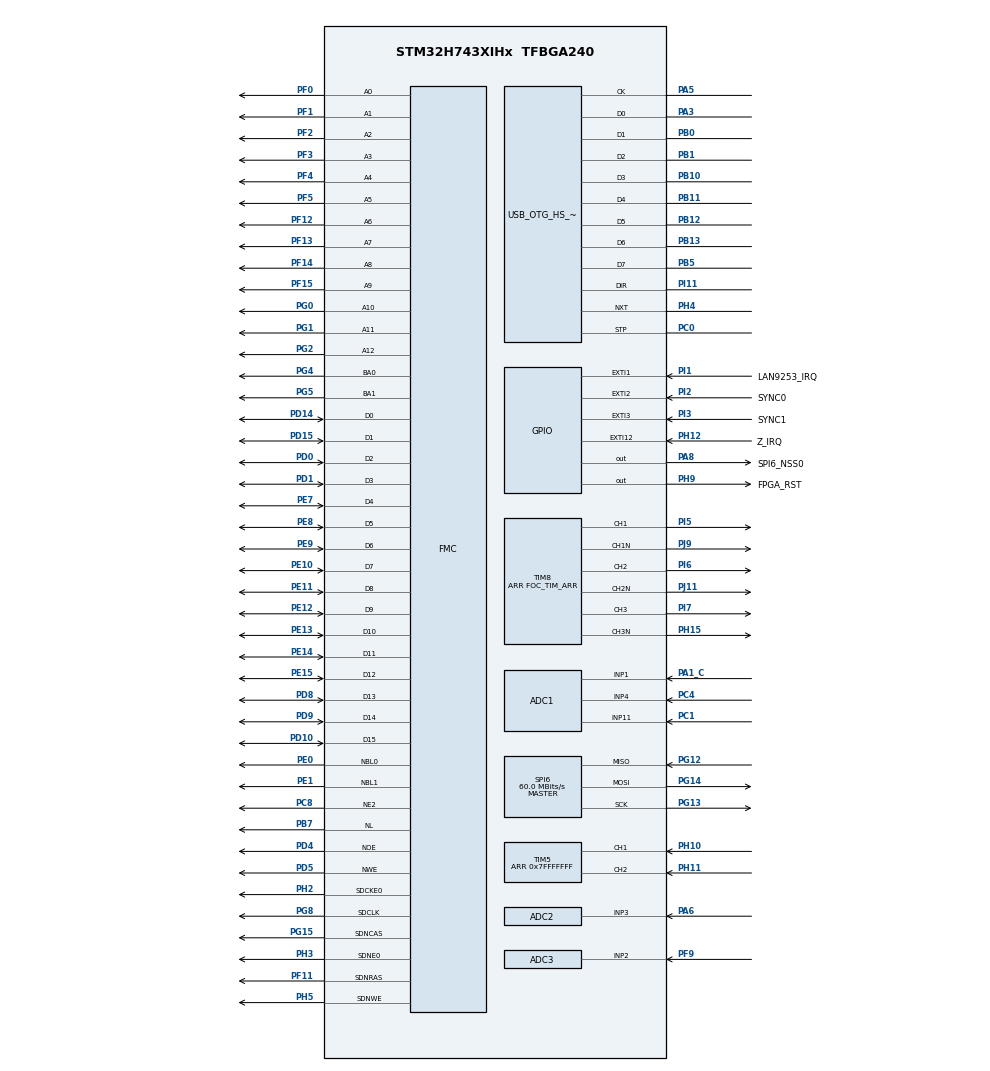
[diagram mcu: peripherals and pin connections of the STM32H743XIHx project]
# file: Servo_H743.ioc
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ADC1.Channel-12\#ChannelRegularConversion=ADC_CHANNEL_4
ADC1.Channel-13\#ChannelRegularConversion=ADC_CHANNEL_11
ADC1.ContinuousConvMode=ENABLE
ADC1.ConversionDataManagement=ADC_CONVERSIONDATA_DMA_CIRCULAR
ADC1.EnableInjectedConversion=ENABLE
ADC1.EnableInjectedOversampling=ENABLE
ADC1.EnableRegularConversion=ENABLE
ADC1.ExternalTrigConv=ADC_EXTERNALTRIG_T8_TRGO
ADC1.InjNumberOfConversion=1
ADC1.InjOversamplingRatio=4
ADC1.InjOversamplingRightShift=ADC_RIGHTBITSHIFT_2
ADC1.InjectedChannel-9\#ChannelInjectedConversion=ADC_CHANNEL_1
ADC1.InjectedOffsetNumber-9\#ChannelInjectedConversion=ADC_OFFSET_NONE
ADC1.InjectedOffsetSaturation-9\#ChannelInjectedConversion=DISABLE
ADC1.InjectedOffsetSignedSaturation-9\#ChannelInjectedConversion=DISABLE
ADC1.InjectedRank-9\#ChannelInjectedConversion=1
ADC1.InjectedSamplingTime-9\#ChannelInjectedConversion=ADC_SAMPLETIME_1CYCLE_5
ADC1.NbrOfConversion=2
ADC1.NbrOfConversionFlag=1
ADC1.OffsetNumber-12\#ChannelRegularConversion=ADC_OFFSET_NONE
ADC1.OffsetNumber-13\#ChannelRegularConversion=ADC_OFFSET_NONE
ADC1.OffsetSignedSaturation-12\#ChannelRegularConversion=DISABLE
ADC1.OffsetSignedSaturation-13\#ChannelRegularConversion=DISABLE
ADC1.Overrun=ADC_OVR_DATA_OVERWRITTEN
ADC1.OversamplingMode=ENABLE
ADC1.Rank-12\#ChannelRegularConversion=1
ADC1.Rank-13\#ChannelRegularConversion=2
ADC1.Ratio=4
ADC1.RightBitShift=ADC_RIGHTBITSHIFT_2
ADC1.SamplingTime-12\#ChannelRegularConversion=ADC_SAMPLETIME_8CYCLES_5
ADC1.SamplingTime-13\#ChannelRegularConversion=ADC_SAMPLETIME_8CYCLES_5
ADC1.master=1
ADC2.ClockPrescaler=ADC_CLOCK_ASYNC_DIV1
ADC2.EnableInjectedConversion=ENABLE
ADC2.EnableInjectedOversampling=ENABLE
ADC2.EnableRegularConversion=DISABLE
ADC2.ExternalTrigInjecConv=ADC_INJECTED_SOFTWARE_START
ADC2.InjNumberOfConversion=1
ADC2.InjOversamplingRatio=4
ADC2.InjOversamplingRightShift=ADC_RIGHTBITSHIFT_2
ADC2.InjectedChannel-1\#ChannelInjectedConversion=ADC_CHANNEL_3
ADC2.InjectedOffsetNumber-1\#ChannelInjectedConversion=ADC_OFFSET_NONE
ADC2.InjectedOffsetSaturation-1\#ChannelInjectedConversion=DISABLE
ADC2.InjectedOffsetSignedSaturation-1\#ChannelInjectedConversion=DISABLE
ADC2.InjectedRank-1\#ChannelInjectedConversion=1
ADC2.InjectedSamplingTime-1\#ChannelInjectedConversion=ADC_SAMPLETIME_1CYCLE_5
ADC3.EnableInjectedConversion=ENABLE
ADC3.EnableInjectedOversampling=ENABLE
ADC3.EnableRegularConversion=DISABLE
ADC3.InjNumberOfConversion=1
ADC3.InjOversamplingRatio=4
ADC3.InjOversamplingRightShift=ADC_RIGHTBITSHIFT_2
ADC3.InjectedChannel-3\#ChannelInjectedConversion=ADC_CHANNEL_2
ADC3.InjectedOffsetNumber-3\#ChannelInjectedConversion=ADC_OFFSET_NONE
ADC3.InjectedOffsetSaturation-3\#ChannelInjectedConversion=DISABLE
ADC3.InjectedOffsetSignedSaturation-3\#ChannelInjectedConversion=DISABLE
ADC3.InjectedRank-3\#ChannelInjectedConversion=1
ADC3.InjectedSamplingTime-3\#ChannelInjectedConversion=ADC_SAMPLETIME_1CYCLE_5
CORTEX_M7.AccessPermission_S-Cortex_Memory_Protection_Unit_Region1_Settings_S=MPU_REGION_PRIV_RW
CORTEX_M7.AccessPermission_S-Cortex_Memory_Protection_Unit_Region2_Settings_S=MPU_REGION_PRIV_RO
CORTEX_M7.BaseAddress_S-Cortex_Memory_Protection_Unit_Region1_Settings_S=0xC0000000
CORTEX_M7.BaseAddress_S-Cortex_Memory_Protection_Unit_Region2_Settings_S=0x64000000
CORTEX_M7.CPU_DCache=Enabled
CORTEX_M7.CPU_ICache=Enabled
CORTEX_M7.Enable_S-Cortex_Memory_Protection_Unit_Region1_Settings_S=MPU_REGION_ENABLE
CORTEX_M7.Enable_S-Cortex_Memory_Protection_Unit_Region2_Settings_S=MPU_REGION_ENABLE
CORTEX_M7.Enable_S-Cortex_Memory_Protection_Unit_Region3_Settings_S=__NULL
CORTEX_M7.IsBufferable_S-Cortex_Memory_Protection_Unit_Region1_Settings_S=MPU_ACCESS_BUFFERABLE
CORTEX_M7.IsBufferable_S-Cortex_Memory_Protection_Unit_Region2_Settings_S=MPU_ACCESS_NOT_BUFFERABLE
CORTEX_M7.IsBufferable_Spec=MPU_ACCESS_NOT_BUFFERABLE
CORTEX_M7.IsCacheable_S-Cortex_Memory_Protection_Unit_Region2_Settings_S=MPU_ACCESS_NOT_CACHEABLE
CORTEX_M7.IsCacheable_Spec=MPU_ACCESS_NOT_CACHEABLE
CORTEX_M7.Size_S-Cortex_Memory_Protection_Unit_Region1_Settings_S=MPU_REGION_SIZE_32MB
CORTEX_M7.Size_S-Cortex_Memory_Protection_Unit_Region2_Settings_S=MPU_REGION_SIZE_128KB
CORTEX_M7.default_mode_Activation=1
Dma.ADC1.0.Direction=DMA_PERIPH_TO_MEMORY
Dma.ADC1.0.EventEnable=DISABLE
Dma.ADC1.0.FIFOMode=DMA_FIFOMODE_ENABLE
Dma.ADC1.0.FIFOThreshold=DMA_FIFO_THRESHOLD_HALFFULL
Dma.ADC1.0.Instance=DMA1_Stream0
Dma.ADC1.0.MemBurst=DMA_MBURST_SINGLE
Dma.ADC1.0.MemDataAlignment=DMA_MDATAALIGN_WORD
Dma.ADC1.0.MemInc=DMA_MINC_ENABLE
Dma.ADC1.0.Mode=DMA_CIRCULAR
Dma.ADC1.0.PeriphBurst=DMA_PBURST_SINGLE
Dma.ADC1.0.PeriphDataAlignment=DMA_PDATAALIGN_WORD
Dma.ADC1.0.PeriphInc=DMA_PINC_DISABLE
Dma.ADC1.0.Polarity=HAL_DMAMUX_REQ_GEN_RISING
Dma.ADC1.0.Priority=DMA_PRIORITY_LOW
Dma.ADC1.0.RequestNumber=1
Dma.ADC1.0.SignalID=NONE
Dma.ADC1.0.SyncEnable=DISABLE
Dma.ADC1.0.SyncPolarity=HAL_DMAMUX_SYNC_NO_EVENT
Dma.ADC1.0.SyncRequestNumber=1
Dma.ADC1.0.SyncSignalID=NONE
Dma.Request0=ADC1
FMC.AddressHoldTime1=1
FMC.AddressSetupTime1=1
FMC.BusTurnAroundDuration1=0
FMC.CASLatency1=FMC_SDRAM_CAS_LATENCY_3
FMC.ColumnBitsNumber1=FMC_SDRAM_COLUMN_BITS_NUM_9
FMC.DataSetupTime1=8
FMC.ExitSelfRefreshDelay1=11
FMC.LoadToActiveDelay1=2
FMC.RCDDelay1=3
FMC.RPDelay1=3
FMC.ReadBurst1=FMC_SDRAM_RBURST_ENABLE
FMC.ReadPipeDelay1=FMC_SDRAM_RPIPE_DELAY_0
FMC.RowCycleDelay1=9
FMC.SDClockPeriod1=FMC_SDRAM_CLOCK_PERIOD_2
FMC.SelfRefreshTime1=7
FMC.WriteOperation1=FMC_WRITE_OPERATION_DISABLE
FMC.WriteRecoveryTime1=4
Mcu.Family=STM32H7
Mcu.Name=STM32H743XIHx
Mcu.Package=TFBGA240
Mcu.UserConstants=FOC_TIM_ARR,6000;FOC_DT,47;FOC_CTRL_FREQ,20000
NVIC.DMA1_Stream0_IRQn=true\:0\:0\:true\:false\:true\:false\:true\:true
NVIC.EXTI15_10_IRQn=true\:1\:0\:true\:false\:true\:true\:true\:true
NVIC.EXTI1_IRQn=true\:0\:0\:false\:false\:true\:true\:true\:true
NVIC.EXTI2_IRQn=true\:0\:0\:false\:false\:true\:true\:true\:true
NVIC.EXTI3_IRQn=true\:0\:0\:false\:false\:true\:true\:true\:true
NVIC.OTG_HS_IRQn=true\:0\:0\:false\:false\:true\:false\:true\:true
NVIC.PriorityGroup=NVIC_PRIORITYGROUP_4
NVIC.TIM2_IRQn=true\:1\:0\:true\:false\:true\:true\:true\:true
NVIC.TIM8_UP_TIM13_IRQn=true\:2\:0\:true\:false\:true\:true\:true\:true
PA1_C.Signal=ADCx_INP1
PA3.Mode=Device_HS
PA3.Signal=USB_OTG_HS_ULPI_D0
PA5.Mode=Device_HS
PA5.Signal=USB_OTG_HS_ULPI_CK
PA6.Signal=ADCx_INP3
PA8.GPIO_Label=SPI6_NSS0
PA8.GPIO_PuPd=GPIO_PULLUP
PA8.Signal=GPIO_Output
PB0.Mode=Device_HS
PB0.Signal=USB_OTG_HS_ULPI_D1
PB1.Mode=Device_HS
PB1.Signal=USB_OTG_HS_ULPI_D2
PB10.Mode=Device_HS
PB10.Signal=USB_OTG_HS_ULPI_D3
PB11.Mode=Device_HS
PB11.Signal=USB_OTG_HS_ULPI_D4
PB12.Mode=Device_HS
PB12.Signal=USB_OTG_HS_ULPI_D5
PB13.Mode=Device_HS
PB13.Signal=USB_OTG_HS_ULPI_D6
PB5.Mode=Device_HS
PB5.Signal=USB_OTG_HS_ULPI_D7
PB7.Signal=FMC_NL
PC0.Mode=Device_HS
PC0.Signal=USB_OTG_HS_ULPI_STP
PC1.Signal=ADCx_INP11
PC4.Signal=ADCx_INP4
PC8.Mode=NorPsramChipSelect2_1
PC8.Signal=FMC_NE2
PD0.Signal=FMC_D2_DA2
PD1.Signal=FMC_D3_DA3
PD10.Signal=FMC_D15_DA15
PD14.Signal=FMC_D0_DA0
PD15.Signal=FMC_D1_DA1
PD4.Signal=FMC_NOE
PD5.Signal=FMC_NWE
PD8.Signal=FMC_D13_DA13
PD9.Signal=FMC_D14_DA14
PE0.Signal=FMC_NBL0
PE1.Signal=FMC_NBL1
PE10.Signal=FMC_D7_DA7
PE11.Signal=FMC_D8_DA8
PE12.Signal=FMC_D9_DA9
PE13.Signal=FMC_D10_DA10
PE14.Signal=FMC_D11_DA11
PE15.Signal=FMC_D12_DA12
PE7.Signal=FMC_D4_DA4
PE8.Signal=FMC_D5_DA5
PE9.Signal=FMC_D6_DA6
PF0.Signal=FMC_A0
PF1.Signal=FMC_A1
PF11.Signal=FMC_SDNRAS
PF12.Signal=FMC_A6
PF13.Signal=FMC_A7
PF14.Signal=FMC_A8
PF15.Signal=FMC_A9
PF2.Signal=FMC_A2
PF3.Signal=FMC_A3
PF4.Signal=FMC_A4
PF5.Signal=FMC_A5
PF9.Mode=IN2-Single-Ended
PF9.Signal=ADC3_INP2
PG0.Signal=FMC_A10
PG1.Signal=FMC_A11
PG12.GPIO_Speed=GPIO_SPEED_FREQ_MEDIUM
PG12.Mode=Full_Duplex_Master
PG12.Signal=SPI6_MISO
PG13.GPIO_PuPd=GPIO_PULLDOWN
PG13.GPIO_Speed=GPIO_SPEED_FREQ_MEDIUM
PG13.Mode=Full_Duplex_Master
PG13.Signal=SPI6_SCK
PG14.GPIO_Speed=GPIO_SPEED_FREQ_MEDIUM
PG14.Mode=Full_Duplex_Master
PG14.Signal=SPI6_MOSI
PG15.Signal=FMC_SDNCAS
PG2.Signal=FMC_A12
PG4.Signal=FMC_A14_BA0
PG5.Signal=FMC_A15_BA1
PG8.Signal=FMC_SDCLK
PH0-OSC_IN\ (PH0).Mode=HSE-External-Clock-Source
PH0-OSC_IN\ (PH0).Signal=RCC_OSC_IN
PH10.Signal=S_TIM5_CH1
PH11.Signal=S_TIM5_CH2
PH12.GPIO_Label=Z_IRQ
PH12.GPIO_PuPd=GPIO_PULLUP
PH12.Signal=GPXTI12
PH15.Mode=PWM Generation3 CH3 CH3N
PH15.Signal=TIM8_CH3N
PH2.Mode=SdramChipSelect1_1
PH2.Signal=FMC_SDCKE0
PH3.Mode=SdramChipSelect1_1
PH3.Signal=FMC_SDNE0
PH4.Mode=Device_HS
PH4.Signal=USB_OTG_HS_ULPI_NXT
PH5.Signal=FMC_SDNWE
PH9.GPIO_Label=FPGA_RST
PH9.GPIO_PuPd=GPIO_PULLUP
PH9.Signal=GPIO_Output
PI1.GPIO_Label=LAN9253_IRQ
PI1.GPIO_ModeDefaultEXTI=GPIO_MODE_IT_FALLING
PI1.GPIO_PuPd=GPIO_PULLUP
PI1.Signal=GPXTI1
PI11.Mode=Device_HS
PI11.Signal=USB_OTG_HS_ULPI_DIR
PI2.GPIO_Label=SYNC0
PI2.GPIO_ModeDefaultEXTI=GPIO_MODE_IT_FALLING
PI2.GPIO_PuPd=GPIO_PULLUP
PI2.Signal=GPXTI2
PI3.GPIO_Label=SYNC1
PI3.GPIO_ModeDefaultEXTI=GPIO_MODE_IT_FALLING
PI3.GPIO_PuPd=GPIO_PULLUP
PI3.Signal=GPXTI3
PI5.Signal=S_TIM8_CH1
PI6.Signal=S_TIM8_CH2
PI7.Signal=S_TIM8_CH3
PJ11.Mode=PWM Generation2 CH2 CH2N
PJ11.Signal=TIM8_CH2N
PJ9.Mode=PWM Generation1 CH1 CH1N
PJ9.Signal=TIM8_CH1N
ProjectManager.HeapSize=0x10000
ProjectManager.StackSize=0x400
ProjectManager.TargetToolchain=MDK-ARM V5.32
RCC.ADCCLockSelection=RCC_ADCCLKSOURCE_PLL3
RCC.ADCFreq_Value=80000000
RCC.APB1Freq_Value=120000000
RCC.APB2Freq_Value=120000000
RCC.APB3Freq_Value=120000000
RCC.APB4Freq_Value=120000000
RCC.CortexFreq_Value=480000000
RCC.D1PPRE=RCC_APB3_DIV2
RCC.D2PPRE1=RCC_APB1_DIV2
RCC.D2PPRE2=RCC_APB2_DIV2
RCC.D3PPRE=RCC_APB4_DIV2
RCC.DIVM1=12
RCC.DIVM2=12
RCC.DIVM3=12
RCC.DIVN1=480
RCC.DIVN2=300
RCC.DIVN3=80
RCC.DIVP2=5
RCC.DIVQ1=20
RCC.EnbaleCSS=true
RCC.FMCCLockSelection=RCC_FMCCLKSOURCE_PLL2
RCC.HCLKFreq_Value=240000000
RCC.HPRE=RCC_HCLK_DIV2
RCC.HSE_VALUE=24000000
RCC.PLLSourceVirtual=RCC_PLLSOURCE_HSE
RCC.ProductRev=revV
RCC.SPI123CLockSelection=RCC_SPI123CLKSOURCE_PLL2
RCC.SYSCLKFreq_VALUE=480000000
RCC.SYSCLKSource=RCC_SYSCLKSOURCE_PLLCLK
RCC.USBFreq_Value=48000000
SH.ADCx_INP1.0=ADC1_INP1,IN1-Single-Ended
SH.ADCx_INP11.0=ADC1_INP11,IN11-Single-Ended
SH.ADCx_INP3.0=ADC2_INP3,IN3-Single-Ended
SH.ADCx_INP4.0=ADC1_INP4,IN4-Single-Ended
SH.FMC_A0.0=FMC_A0,13b-sda1
SH.FMC_A1.0=FMC_A1,13b-sda1
SH.FMC_A10.0=FMC_A10,13b-sda1
SH.FMC_A11.0=FMC_A11,13b-sda1
SH.FMC_A12.0=FMC_A12,13b-sda1
SH.FMC_A14_BA0.0=FMC_BA0,FourSdramBanks1
SH.FMC_A15_BA1.0=FMC_BA1,FourSdramBanks1
SH.FMC_A2.0=FMC_A2,13b-sda1
SH.FMC_A3.0=FMC_A3,13b-sda1
SH.FMC_A4.0=FMC_A4,13b-sda1
SH.FMC_A5.0=FMC_A5,13b-sda1
SH.FMC_A6.0=FMC_A6,13b-sda1
SH.FMC_A7.0=FMC_A7,13b-sda1
SH.FMC_A8.0=FMC_A8,13b-sda1
SH.FMC_A9.0=FMC_A9,13b-sda1
SH.FMC_D0_DA0.0=FMC_D0,sd-16b-d1
SH.FMC_D0_DA0.1=FMC_DA0,16b-da1
SH.FMC_D10_DA10.0=FMC_D10,sd-16b-d1
SH.FMC_D10_DA10.1=FMC_DA10,16b-da1
SH.FMC_D11_DA11.0=FMC_D11,sd-16b-d1
SH.FMC_D11_DA11.1=FMC_DA11,16b-da1
SH.FMC_D12_DA12.0=FMC_D12,sd-16b-d1
SH.FMC_D12_DA12.1=FMC_DA12,16b-da1
SH.FMC_D13_DA13.0=FMC_D13,sd-16b-d1
SH.FMC_D13_DA13.1=FMC_DA13,16b-da1
SH.FMC_D14_DA14.0=FMC_D14,sd-16b-d1
SH.FMC_D14_DA14.1=FMC_DA14,16b-da1
SH.FMC_D15_DA15.0=FMC_D15,sd-16b-d1
SH.FMC_D15_DA15.1=FMC_DA15,16b-da1
SH.FMC_D1_DA1.0=FMC_D1,sd-16b-d1
SH.FMC_D1_DA1.1=FMC_DA1,16b-da1
SH.FMC_D2_DA2.0=FMC_D2,sd-16b-d1
SH.FMC_D2_DA2.1=FMC_DA2,16b-da1
SH.FMC_D3_DA3.0=FMC_D3,sd-16b-d1
SH.FMC_D3_DA3.1=FMC_DA3,16b-da1
SH.FMC_D4_DA4.0=FMC_D4,sd-16b-d1
SH.FMC_D4_DA4.1=FMC_DA4,16b-da1
SH.FMC_D5_DA5.0=FMC_D5,sd-16b-d1
SH.FMC_D5_DA5.1=FMC_DA5,16b-da1
SH.FMC_D6_DA6.0=FMC_D6,sd-16b-d1
SH.FMC_D6_DA6.1=FMC_DA6,16b-da1
SH.FMC_D7_DA7.0=FMC_D7,sd-16b-d1
SH.FMC_D7_DA7.1=FMC_DA7,16b-da1
SH.FMC_D8_DA8.0=FMC_D8,sd-16b-d1
SH.FMC_D8_DA8.1=FMC_DA8,16b-da1
SH.FMC_D9_DA9.0=FMC_D9,sd-16b-d1
SH.FMC_D9_DA9.1=FMC_DA9,16b-da1
SH.FMC_NBL0.0=FMC_NBL0,Sd2ByteEnable1
SH.FMC_NBL1.0=FMC_NBL1,Sd2ByteEnable1
SH.FMC_NL.0=FMC_NL,AddressValid1
SH.FMC_NOE.0=FMC_NOE,MuxedPsram1
SH.FMC_NWE.0=FMC_NWE,MuxedPsram1
SH.FMC_SDCLK.0=FMC_SDCLK,13b-sda1
SH.FMC_SDNCAS.0=FMC_SDNCAS,13b-sda1
SH.FMC_SDNRAS.0=FMC_SDNRAS,13b-sda1
SH.FMC_SDNWE.0=FMC_SDNWE,13b-sda1
SH.S_TIM5_CH1.0=TIM5_CH1,Encoder_Interface
SH.S_TIM5_CH2.0=TIM5_CH2,Encoder_Interface
SH.S_TIM8_CH1.0=TIM8_CH1,PWM Generation1 CH1 CH1N
SH.S_TIM8_CH2.0=TIM8_CH2,PWM Generation2 CH2 CH2N
SH.S_TIM8_CH3.0=TIM8_CH3,PWM Generation3 CH3 CH3N
SPI6.CalculateBaudRate=60.0 MBits/s
SPI6.DataSize=SPI_DATASIZE_8BIT
SPI6.Direction=SPI_DIRECTION_2LINES
SPI6.Mode=SPI_MODE_MASTER
SPI6.VirtualType=VM_MASTER
TIM2.Period=120000-1
TIM5.EncoderMode=TIM_ENCODERMODE_TI12
TIM5.IC1Polarity=TIM_ICPOLARITY_RISING
TIM5.Period=0x7FFFFFFF
TIM8.Channel-PWM\ Generation1\ CH1\ CH1N=TIM_CHANNEL_1
TIM8.Channel-PWM\ Generation2\ CH2\ CH2N=TIM_CHANNEL_2
TIM8.Channel-PWM\ Generation3\ CH3\ CH3N=TIM_CHANNEL_3
TIM8.CounterMode=TIM_COUNTERMODE_CENTERALIGNED1
TIM8.DeadTime=FOC_DT
TIM8.LockLevel=TIM_LOCKLEVEL_1
TIM8.Period=FOC_TIM_ARR
TIM8.TIM_MasterOutputTrigger=TIM_TRGO_UPDATE
USB_DEVICE.CLASS_NAME_HS=CDC
USB_DEVICE.VirtualMode-CDC_HS=Cdc
USB_DEVICE.VirtualModeHS=Cdc_HS
USB_OTG_HS.VirtualMode-Device_HS=Device_HS
VP_TIM2_VS_ClockSourceINT.Mode=Internal
VP_TIM8_VS_ClockSourceINT.Mode=Internal
VP_USB_DEVICE_VS_USB_DEVICE_CDC_HS.Mode=CDC_HS
board=custom

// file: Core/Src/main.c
/* USER CODE BEGIN Header */
/**
 ******************************************************************************
 * @file           : main.c
 * @brief          : Main program body
 ******************************************************************************
 * @attention
 *
 * Copyright (c) 2023 STMicroelectronics.
 * All rights reserved.
 *
 * This software is licensed under terms that can be found in the LICENSE file
 * in the root directory of this software component.
 * If no LICENSE file comes with this software, it is provided AS-IS.
 *
 ******************************************************************************
 */
/* USER CODE END Header */
#include "main.h"
#include "adc.h"
#include "dma.h"
#include "spi.h"
#include "tim.h"
#include "usb_device.h"
#include "gpio.h"
#include "fmc.h"

/* USER CODE BEGIN Includes */
#include "MyApplication.h"
#include "applInterface.h"
#include "ecat_def.h"
/* USER CODE END Includes */

/* USER CODE BEGIN PV */
volatile int16_t adc_v[16] __attribute__((section(".bss.ARM.__at_0x64000000")));
// volatile int a[100000] __attribute__((section(".bss.ARM.__at_0xC0000000")));
// volatile int b[100];
/* USER CODE END PV */

void SystemClock_Config(void);
void PeriphCommonClock_Config(void);
static void MPU_Config(void);
/* USER CODE BEGIN PFP */
void servo_init();
void VPC_Loop();
/* USER CODE END PFP */

int main(void)
{

  /* MPU Configuration--------------------------------------------------------*/
  MPU_Config();

  /* Enable I-Cache---------------------------------------------------------*/
  SCB_EnableICache();

  /* Enable D-Cache---------------------------------------------------------*/
  SCB_EnableDCache();

  /* MCU Configuration--------------------------------------------------------*/

  /* Reset of all peripherals, Initializes the Flash interface and the Systick. */
  HAL_Init();

  /* Configure the system clock */
  SystemClock_Config();

/* Configure the peripherals common clocks */
  PeriphCommonClock_Config();

  /* Initialize all configured peripherals */
  MX_GPIO_Init();
  MX_DMA_Init();
  MX_ADC2_Init();
  MX_ADC3_Init();
  MX_TIM8_Init();
  MX_USB_DEVICE_Init();
  MX_TIM5_Init();
  MX_FMC_Init();
  MX_TIM2_Init();
  MX_ADC1_Init();
  MX_SPI6_Init();
  /* USER CODE BEGIN 2 */
  HAL_ADCEx_Calibration_Start(&hadc1, ADC_CALIB_OFFSET_LINEARITY,
                              ADC_SINGLE_ENDED);
  HAL_ADCEx_Calibration_Start(&hadc2, ADC_CALIB_OFFSET_LINEARITY,
                              ADC_SINGLE_ENDED);
  HAL_ADCEx_Calibration_Start(&hadc3, ADC_CALIB_OFFSET_LINEARITY,
                              ADC_SINGLE_ENDED);
  HAL_TIM_Base_Start_IT(&htim8);
  servo_init();
	//HAL_ADC_Start_DMA(&hadc1,(uint32_t *)&servo.safeguard.adcValue,10);
  // EtherCAT
  HW_Init();
  MainInit();
  // for (int i = 0; i < 10000; i++) {
  //   a[i] = i;
  // }
  // for (int i = 0; i < 100; i++) {
  //   b[i] = a[i];
  // }
  HAL_Delay(1);
  HAL_GPIO_WritePin(FPGA_RST_GPIO_Port, FPGA_RST_Pin, 0);
  HAL_Delay(1);
  HAL_GPIO_WritePin(FPGA_RST_GPIO_Port, FPGA_RST_Pin, 1);
  /* USER CODE END 2 */

  /* Infinite loop */
  /* USER CODE BEGIN WHILE */
  while (1) {
    MainLoop();
    VPC_Loop();
    /* USER CODE END WHILE */

  }
}

void SystemClock_Config(void)
{
  RCC_OscInitTypeDef RCC_OscInitStruct = {0};
  RCC_ClkInitTypeDef RCC_ClkInitStruct = {0};

  /** Supply configuration update enable
  */
  HAL_PWREx_ConfigSupply(PWR_LDO_SUPPLY);

  /** Configure the main internal regulator output voltage
  */
  __HAL_PWR_VOLTAGESCALING_CONFIG(PWR_REGULATOR_VOLTAGE_SCALE1);

  while(!__HAL_PWR_GET_FLAG(PWR_FLAG_VOSRDY)) {}

  __HAL_RCC_SYSCFG_CLK_ENABLE();
  __HAL_PWR_VOLTAGESCALING_CONFIG(PWR_REGULATOR_VOLTAGE_SCALE0);

  while(!__HAL_PWR_GET_FLAG(PWR_FLAG_VOSRDY)) {}

  /** Initializes the RCC Oscillators according to the specified parameters
  * in the RCC_OscInitTypeDef structure.
  */
  RCC_OscInitStruct.OscillatorType = RCC_OSCILLATORTYPE_HSE;
  RCC_OscInitStruct.HSEState = RCC_HSE_BYPASS;
  RCC_OscInitStruct.PLL.PLLState = RCC_PLL_ON;
  RCC_OscInitStruct.PLL.PLLSource = RCC_PLLSOURCE_HSE;
  RCC_OscInitStruct.PLL.PLLM = 12;
  RCC_OscInitStruct.PLL.PLLN = 480;
  RCC_OscInitStruct.PLL.PLLP = 2;
  RCC_OscInitStruct.PLL.PLLQ = 20;
  RCC_OscInitStruct.PLL.PLLR = 2;
  RCC_OscInitStruct.PLL.PLLRGE = RCC_PLL1VCIRANGE_1;
  RCC_OscInitStruct.PLL.PLLVCOSEL = RCC_PLL1VCOWIDE;
  RCC_OscInitStruct.PLL.PLLFRACN = 0;
  if (HAL_RCC_OscConfig(&RCC_OscInitStruct) != HAL_OK)
  {
    Error_Handler();
  }

  /** Initializes the CPU, AHB and APB buses clocks
  */
  RCC_ClkInitStruct.ClockType = RCC_CLOCKTYPE_HCLK|RCC_CLOCKTYPE_SYSCLK
                              |RCC_CLOCKTYPE_PCLK1|RCC_CLOCKTYPE_PCLK2
                              |RCC_CLOCKTYPE_D3PCLK1|RCC_CLOCKTYPE_D1PCLK1;
  RCC_ClkInitStruct.SYSCLKSource = RCC_SYSCLKSOURCE_PLLCLK;
  RCC_ClkInitStruct.SYSCLKDivider = RCC_SYSCLK_DIV1;
  RCC_ClkInitStruct.AHBCLKDivider = RCC_HCLK_DIV2;
  RCC_ClkInitStruct.APB3CLKDivider = RCC_APB3_DIV2;
  RCC_ClkInitStruct.APB1CLKDivider = RCC_APB1_DIV2;
  RCC_ClkInitStruct.APB2CLKDivider = RCC_APB2_DIV2;
  RCC_ClkInitStruct.APB4CLKDivider = RCC_APB4_DIV2;

  if (HAL_RCC_ClockConfig(&RCC_ClkInitStruct, FLASH_LATENCY_4) != HAL_OK)
  {
    Error_Handler();
  }

  /** Enables the Clock Security System
  */
  HAL_RCC_EnableCSS();
}

void PeriphCommonClock_Config(void)
{
  RCC_PeriphCLKInitTypeDef PeriphClkInitStruct = {0};

  /** Initializes the peripherals clock
  */
  PeriphClkInitStruct.PeriphClockSelection = RCC_PERIPHCLK_ADC;
  PeriphClkInitStruct.PLL3.PLL3M = 12;
  PeriphClkInitStruct.PLL3.PLL3N = 80;
  PeriphClkInitStruct.PLL3.PLL3P = 2;
  PeriphClkInitStruct.PLL3.PLL3Q = 2;
  PeriphClkInitStruct.PLL3.PLL3R = 2;
  PeriphClkInitStruct.PLL3.PLL3RGE = RCC_PLL3VCIRANGE_1;
  PeriphClkInitStruct.PLL3.PLL3VCOSEL = RCC_PLL3VCOMEDIUM;
  PeriphClkInitStruct.PLL3.PLL3FRACN = 0;
  PeriphClkInitStruct.AdcClockSelection = RCC_ADCCLKSOURCE_PLL3;
  if (HAL_RCCEx_PeriphCLKConfig(&PeriphClkInitStruct) != HAL_OK)
  {
    Error_Handler();
  }
}

/* MPU Configuration */

void MPU_Config(void)
{
  MPU_Region_InitTypeDef MPU_InitStruct = {0};

  /* Disables the MPU */
  HAL_MPU_Disable();

  /** Initializes and configures the Region and the memory to be protected
  */
  MPU_InitStruct.Enable = MPU_REGION_ENABLE;
  MPU_InitStruct.Number = MPU_REGION_NUMBER0;
  MPU_InitStruct.BaseAddress = 0x0;
  MPU_InitStruct.Size = MPU_REGION_SIZE_4GB;
  MPU_InitStruct.SubRegionDisable = 0x87;
  MPU_InitStruct.TypeExtField = MPU_TEX_LEVEL0;
  MPU_InitStruct.AccessPermission = MPU_REGION_NO_ACCESS;
  MPU_InitStruct.DisableExec = MPU_INSTRUCTION_ACCESS_DISABLE;
  MPU_InitStruct.IsShareable = MPU_ACCESS_SHAREABLE;
  MPU_InitStruct.IsCacheable = MPU_ACCESS_NOT_CACHEABLE;
  MPU_InitStruct.IsBufferable = MPU_ACCESS_NOT_BUFFERABLE;

  HAL_MPU_ConfigRegion(&MPU_InitStruct);

  /** Initializes and configures the Region and the memory to be protected
  */
  MPU_InitStruct.Number = MPU_REGION_NUMBER1;
  MPU_InitStruct.BaseAddress = 0xC0000000;
  MPU_InitStruct.Size = MPU_REGION_SIZE_32MB;
  MPU_InitStruct.SubRegionDisable = 0x0;
  MPU_InitStruct.AccessPermission = MPU_REGION_PRIV_RW;
  MPU_InitStruct.DisableExec = MPU_INSTRUCTION_ACCESS_ENABLE;
  MPU_InitStruct.IsShareable = MPU_ACCESS_NOT_SHAREABLE;
  MPU_InitStruct.IsBufferable = MPU_ACCESS_BUFFERABLE;

  HAL_MPU_ConfigRegion(&MPU_InitStruct);

  /** Initializes and configures the Region and the memory to be protected
  */
  MPU_InitStruct.Number = MPU_REGION_NUMBER2;
  MPU_InitStruct.BaseAddress = 0x64000000;
  MPU_InitStruct.Size = MPU_REGION_SIZE_128KB;
  MPU_InitStruct.AccessPermission = MPU_REGION_PRIV_RO;
  MPU_InitStruct.IsBufferable = MPU_ACCESS_NOT_BUFFERABLE;

  HAL_MPU_ConfigRegion(&MPU_InitStruct);
  /* Enables the MPU */
  HAL_MPU_Enable(MPU_PRIVILEGED_DEFAULT);

}

void Error_Handler(void)
{
  __disable_irq();
  while (1) {
  }
}

#ifdef  USE_FULL_ASSERT
/**
  * @brief  Reports the name of the source file and the source line number
  *         where the assert_param error has occurred.
  * @param  file: pointer to the source file name
  * @param  line: assert_param error line source number
  * @retval None
  */
void assert_failed(uint8_t *file, uint32_t line)
{
  /* USER CODE BEGIN 6 */
  /* User can add his own implementation to report the file name and line
     number, ex: printf("Wrong parameters value: file %s on line %d\r\n", file,
     line) */
  /* USER CODE END 6 */
}
#endif /* USE_FULL_ASSERT */
